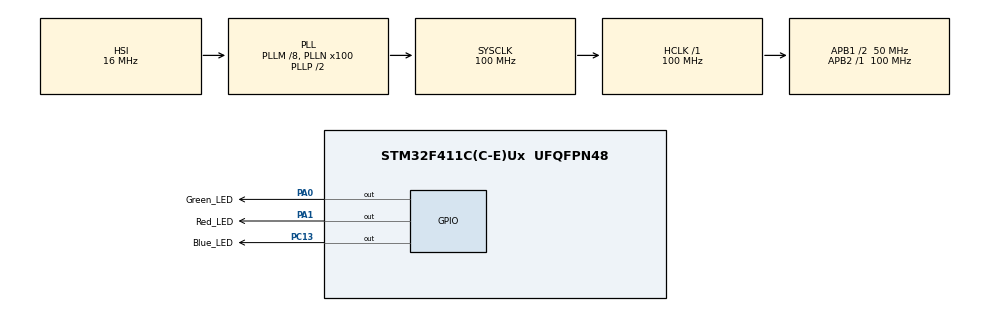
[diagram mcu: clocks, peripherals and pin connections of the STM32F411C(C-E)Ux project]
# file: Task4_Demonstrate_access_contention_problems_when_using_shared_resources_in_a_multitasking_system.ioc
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FREERTOS.Tasks01=defaultTask,24,128,StartDefaultTask,Default,NULL,Dynamic,NULL,NULL;RelLedFlashTs,32,128,RelLedFlashing,Default,NULL,Dynamic,NULL,NULL;GreenLedFlashTs,24,128,GreenLedFlass,Default,NULL,Dynamic,NULL,NULL
FREERTOS.configUSE_NEWLIB_REENTRANT=1
Mcu.Family=STM32F4
Mcu.Name=STM32F411C(C-E)Ux
Mcu.Package=UFQFPN48
NVIC.PriorityGroup=NVIC_PRIORITYGROUP_4
NVIC.TIM4_IRQn=true\:15\:0\:false\:false\:true\:false\:false\:true\:true
NVIC.TimeBase=TIM4_IRQn
NVIC.TimeBaseIP=TIM4
PA0-WKUP.GPIO_Label=Green_LED
PA0-WKUP.Signal=GPIO_Output
PA1.GPIO_Label=Red_LED
PA1.Signal=GPIO_Output
PA13.Mode=Serial_Wire
PA13.Signal=SYS_JTMS-SWDIO
PA14.Mode=Serial_Wire
PA14.Signal=SYS_JTCK-SWCLK
PC13-ANTI_TAMP.GPIO_Label=Blue_LED
PC13-ANTI_TAMP.Signal=GPIO_Output
ProjectManager.HeapSize=0x200
ProjectManager.StackSize=0x400
ProjectManager.TargetToolchain=STM32CubeIDE
RCC.48MHZClocksFreq_Value=50000000
RCC.AHBFreq_Value=100000000
RCC.APB1CLKDivider=RCC_HCLK_DIV2
RCC.APB1Freq_Value=50000000
RCC.APB1TimFreq_Value=100000000
RCC.APB2Freq_Value=100000000
RCC.APB2TimFreq_Value=100000000
RCC.CortexFreq_Value=100000000
RCC.HCLKFreq_Value=100000000
RCC.HSE_VALUE=25000000
RCC.HSI_VALUE=16000000
RCC.LSE_VALUE=32768
RCC.PLLM=8
RCC.PLLN=100
RCC.SYSCLKFreq_VALUE=100000000
RCC.SYSCLKSource=RCC_SYSCLKSOURCE_PLLCLK
RCC.VCOOutputFreq_Value=200000000
VP_FREERTOS_VS_CMSIS_V2.Mode=CMSIS_V2
VP_SYS_VS_tim4.Mode=TIM4
board=custom

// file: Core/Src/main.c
/* USER CODE BEGIN Header */
/**
  ******************************************************************************
  * @file           : main.c
  * @brief          : Main program body
  ******************************************************************************
  * @attention
  *
  * Copyright (c) 2024 STMicroelectronics.
  * All rights reserved.
  *
  * This software is licensed under terms that can be found in the LICENSE file
  * in the root directory of this software component.
  * If no LICENSE file comes with this software, it is provided AS-IS.
  *
  ******************************************************************************
  */
/* USER CODE END Header */
#include "main.h"
#include "cmsis_os.h"

/* Definitions for defaultTask */
osThreadId_t defaultTaskHandle;
const osThreadAttr_t defaultTask_attributes = {
  .name = "defaultTask",
  .stack_size = 128 * 4,
  .priority = (osPriority_t) osPriorityNormal,
};
/* Definitions for RelLedFlashTs */
osThreadId_t RelLedFlashTsHandle;
const osThreadAttr_t RelLedFlashTs_attributes = {
  .name = "RelLedFlashTs",
  .stack_size = 128 * 4,
  .priority = (osPriority_t) osPriorityAboveNormal,
};
/* Definitions for GreenLedFlashTs */
osThreadId_t GreenLedFlashTsHandle;
const osThreadAttr_t GreenLedFlashTs_attributes = {
  .name = "GreenLedFlashTs",
  .stack_size = 128 * 4,
  .priority = (osPriority_t) osPriorityNormal,
};

void SystemClock_Config(void);
static void MX_GPIO_Init(void);
void StartDefaultTask(void *argument);
void RelLedFlashing(void *argument);
void GreenLedFlass(void *argument);

/* USER CODE BEGIN PFP */
uint8_t flagg = 1;
void accessData(){
	if(flagg == 1) flagg = 0;
	else{
		HAL_GPIO_WritePin(Blue_LED_GPIO_Port, Blue_LED_Pin, 0);
//		osDelay(100);
		HAL_Delay(100);
		HAL_GPIO_WritePin(Blue_LED_GPIO_Port, Blue_LED_Pin, 1);
	}
	HAL_Delay(500);
	flagg = 1;
}
/* USER CODE END PFP */

int main(void)
{

  /* MCU Configuration--------------------------------------------------------*/

  /* Reset of all peripherals, Initializes the Flash interface and the Systick. */
  HAL_Init();

  /* Configure the system clock */
  SystemClock_Config();

  /* Initialize all configured peripherals */
  MX_GPIO_Init();
  /* USER CODE BEGIN 2 */
  HAL_GPIO_WritePin(Blue_LED_GPIO_Port, Blue_LED_Pin, 1);
  /* USER CODE END 2 */

  /* Init scheduler */
  osKernelInitialize();

  /* Create the thread(s) */
  /* creation of defaultTask */
  defaultTaskHandle = osThreadNew(StartDefaultTask, NULL, &defaultTask_attributes);

  /* creation of RelLedFlashTs */
  RelLedFlashTsHandle = osThreadNew(RelLedFlashing, NULL, &RelLedFlashTs_attributes);

  /* creation of GreenLedFlashTs */
  GreenLedFlashTsHandle = osThreadNew(GreenLedFlass, NULL, &GreenLedFlashTs_attributes);

  /* Start scheduler */
  osKernelStart();

  /* We should never get here as control is now taken by the scheduler */

  /* Infinite loop */
  while (1)
  {

  }
}

void SystemClock_Config(void)
{
  RCC_OscInitTypeDef RCC_OscInitStruct = {0};
  RCC_ClkInitTypeDef RCC_ClkInitStruct = {0};

  /** Configure the main internal regulator output voltage
  */
  __HAL_RCC_PWR_CLK_ENABLE();
  __HAL_PWR_VOLTAGESCALING_CONFIG(PWR_REGULATOR_VOLTAGE_SCALE1);

  /** Initializes the RCC Oscillators according to the specified parameters
  * in the RCC_OscInitTypeDef structure.
  */
  RCC_OscInitStruct.OscillatorType = RCC_OSCILLATORTYPE_HSI;
  RCC_OscInitStruct.HSIState = RCC_HSI_ON;
  RCC_OscInitStruct.HSICalibrationValue = RCC_HSICALIBRATION_DEFAULT;
  RCC_OscInitStruct.PLL.PLLState = RCC_PLL_ON;
  RCC_OscInitStruct.PLL.PLLSource = RCC_PLLSOURCE_HSI;
  RCC_OscInitStruct.PLL.PLLM = 8;
  RCC_OscInitStruct.PLL.PLLN = 100;
  RCC_OscInitStruct.PLL.PLLP = RCC_PLLP_DIV2;
  RCC_OscInitStruct.PLL.PLLQ = 4;
  if (HAL_RCC_OscConfig(&RCC_OscInitStruct) != HAL_OK)
  {
    Error_Handler();
  }

  /** Initializes the CPU, AHB and APB buses clocks
  */
  RCC_ClkInitStruct.ClockType = RCC_CLOCKTYPE_HCLK|RCC_CLOCKTYPE_SYSCLK
                              |RCC_CLOCKTYPE_PCLK1|RCC_CLOCKTYPE_PCLK2;
  RCC_ClkInitStruct.SYSCLKSource = RCC_SYSCLKSOURCE_PLLCLK;
  RCC_ClkInitStruct.AHBCLKDivider = RCC_SYSCLK_DIV1;
  RCC_ClkInitStruct.APB1CLKDivider = RCC_HCLK_DIV2;
  RCC_ClkInitStruct.APB2CLKDivider = RCC_HCLK_DIV1;

  if (HAL_RCC_ClockConfig(&RCC_ClkInitStruct, FLASH_LATENCY_3) != HAL_OK)
  {
    Error_Handler();
  }
}

static void MX_GPIO_Init(void)
{
  GPIO_InitTypeDef GPIO_InitStruct = {0};

  /* GPIO Ports Clock Enable */
  __HAL_RCC_GPIOC_CLK_ENABLE();
  __HAL_RCC_GPIOA_CLK_ENABLE();

  /*Configure GPIO pin Output Level */
  HAL_GPIO_WritePin(Blue_LED_GPIO_Port, Blue_LED_Pin, GPIO_PIN_RESET);

  /*Configure GPIO pin Output Level */
  HAL_GPIO_WritePin(GPIOA, Green_LED_Pin|Red_LED_Pin, GPIO_PIN_RESET);

  /*Configure GPIO pin : Blue_LED_Pin */
  GPIO_InitStruct.Pin = Blue_LED_Pin;
  GPIO_InitStruct.Mode = GPIO_MODE_OUTPUT_PP;
  GPIO_InitStruct.Pull = GPIO_NOPULL;
  GPIO_InitStruct.Speed = GPIO_SPEED_FREQ_LOW;
  HAL_GPIO_Init(Blue_LED_GPIO_Port, &GPIO_InitStruct);

  /*Configure GPIO pins : Green_LED_Pin Red_LED_Pin */
  GPIO_InitStruct.Pin = Green_LED_Pin|Red_LED_Pin;
  GPIO_InitStruct.Mode = GPIO_MODE_OUTPUT_PP;
  GPIO_InitStruct.Pull = GPIO_NOPULL;
  GPIO_InitStruct.Speed = GPIO_SPEED_FREQ_LOW;
  HAL_GPIO_Init(GPIOA, &GPIO_InitStruct);

}

void StartDefaultTask(void *argument)
{
  for(;;)
  {
    osDelay(1);
  }
}

void RelLedFlashing(void *argument)
{
  /* USER CODE BEGIN RelLedFlashing */
  /* Infinite loop */
  for(;;)
  {
	  HAL_GPIO_WritePin(Red_LED_GPIO_Port, Red_LED_Pin, 1);
//	  taskENTER_CRITICAL();
	  accessData();
//	  taskEXIT_CRITICAL();
	  HAL_GPIO_WritePin(Red_LED_GPIO_Port, Red_LED_Pin, 0);
    osDelay(100);
  }
  /* USER CODE END RelLedFlashing */
}

void GreenLedFlass(void *argument)
{
  /* USER CODE BEGIN GreenLedFlass */
  /* Infinite loop */
  for(;;)
  {
	  HAL_GPIO_WritePin(Green_LED_GPIO_Port, Green_LED_Pin, 1);
//	  taskENTER_CRITICAL();
	  accessData();
//	  taskEXIT_CRITICAL();
	  HAL_GPIO_WritePin(Green_LED_GPIO_Port, Green_LED_Pin, 0);
	  osDelay(500);
  }
  /* USER CODE END GreenLedFlass */
}

void HAL_TIM_PeriodElapsedCallback(TIM_HandleTypeDef *htim)
{
  if (htim->Instance == TIM4) {
    HAL_IncTick();
  }
}

void Error_Handler(void)
{
  __disable_irq();
  while (1)
  {
  }
}
